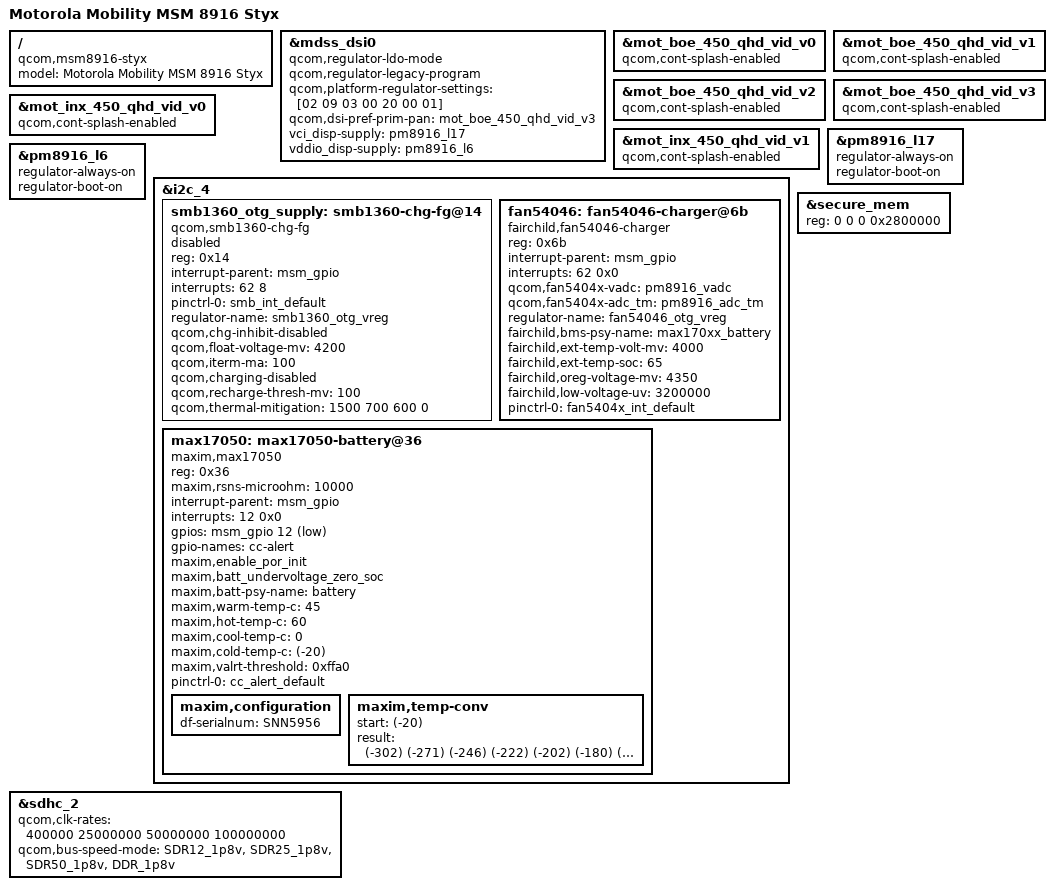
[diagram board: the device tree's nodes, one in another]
/* Copyright (c) 2014, Motorola Mobility LLC. All rights reserved.
*
* This program is free software; you can redistribute it and/or modify
* it under the terms of the GNU General Public License version 2 and
* only version 2 as published by the Free Software Foundation.
*
* This program is distributed in the hope that it will be useful,
* but WITHOUT ANY WARRANTY; without even the implied warranty of
* MERCHANTABILITY or FITNESS FOR A PARTICULAR PURPOSE.  See the
* GNU General Public License for more details.
*/

#include "msm8916-moto-common.dtsi"
#include "msm8916-camera-sensor-styx.dtsi"
#include "dsi-panel-mot-boe-450-qHD-video.dtsi"
#include "dsi-panel-mot-inx-450-qHD-video.dtsi"

/ {
	model = "Motorola Mobility MSM 8916 Styx";
	compatible = "qcom,msm8916-styx", "qcom,msm8916-moto", "qcom,msm8916";
};

&mdss_dsi0 {
	qcom,regulator-ldo-mode;
	qcom,regulator-legacy-program;
	qcom,platform-regulator-settings = [02 09 03 00 20 00 01];
	qcom,dsi-pref-prim-pan = <&mot_boe_450_qhd_vid_v3>;
	vci_disp-supply = <&pm8916_l17>;
	vddio_disp-supply = <&pm8916_l6>;
};

&mot_boe_450_qhd_vid_v0 {
	qcom,cont-splash-enabled;
};

&mot_boe_450_qhd_vid_v1 {
	qcom,cont-splash-enabled;
};

&mot_boe_450_qhd_vid_v2 {
	qcom,cont-splash-enabled;
};

&mot_boe_450_qhd_vid_v3 {
	qcom,cont-splash-enabled;
};

&mot_inx_450_qhd_vid_v0 {
	qcom,cont-splash-enabled;
};

&mot_inx_450_qhd_vid_v1 {
	qcom,cont-splash-enabled;
};

&pm8916_l17 {
	regulator-always-on;
	regulator-boot-on;
};

&pm8916_l6 {
	regulator-always-on;
	regulator-boot-on;
};

&i2c_4 {
	smb1360_otg_supply: smb1360-chg-fg@14 {
		status = "disabled";
		compatible = "qcom,smb1360-chg-fg";
		reg = <0x14>;
		interrupt-parent = <&msm_gpio>;
		interrupts = <62 8>;
		pinctrl-names = "default";
		pinctrl-0 = <&smb_int_default>;
		regulator-name = "smb1360_otg_vreg";

		qcom,chg-inhibit-disabled;
		qcom,float-voltage-mv = <4200>;
		qcom,iterm-ma = <100>;
		qcom,charging-disabled;
		qcom,recharge-thresh-mv = <100>;
		qcom,thermal-mitigation = <1500 700 600 0>;
	};

	fan54046: fan54046-charger@6b {
		compatible = "fairchild,fan54046-charger";
		reg = <0x6b>;

		interrupt-parent = <&msm_gpio>;
		interrupts = <62 0x0>;
		qcom,fan5404x-vadc = <&pm8916_vadc>;
		qcom,fan5404x-adc_tm = <&pm8916_adc_tm>;
		regulator-name = "fan54046_otg_vreg";

		fairchild,bms-psy-name = "max170xx_battery";
		fairchild,ext-temp-volt-mv = <4000>;
		fairchild,ext-temp-soc = <65>;
		fairchild,oreg-voltage-mv = <4350>;
		fairchild,low-voltage-uv = <3200000>;

		pinctrl-names = "default";
		pinctrl-0 = <&fan5404x_int_default>;
	};

	max17050: max17050-battery@36 {
		compatible = "maxim,max17050";
		reg = <0x36>;
		maxim,rsns-microohm = <10000>;

		interrupt-parent = <&msm_gpio>;
		interrupts = <12 0x0>;
		gpios = <&msm_gpio 12 0x11>; /* GPIOF_DIR_IN|GPIOF_EXPORT */
		gpio-names = "cc-alert";

		maxim,enable_por_init;
		maxim,batt_undervoltage_zero_soc;
		maxim,batt-psy-name = "battery";
		maxim,warm-temp-c = <45>;
		maxim,hot-temp-c = <60>;
		maxim,cool-temp-c = <0>;
		maxim,cold-temp-c = <(-20)>;

		maxim,valrt-threshold = <0xffa0>; /* Vmin 3.2V */

		pinctrl-names = "default";
		pinctrl-0 = <&cc_alert_default>;

		maxim,configuration {
			df-serialnum	= "SNN5956";

			/include/ "batterydata-ft40-lg.dtsi"
			/include/ "batterydata-ft40-sony.dtsi"
			/include/ "batterydata-ft40-lishen.dtsi"
		};

		maxim,temp-conv {
			start	= /bits/ 16 <(-20)>;	/* in degrees C */
			result	= /bits/ 16 <
				/* 1/10th C "real" temps corresponding start, start + 1, etc. fuel gauge temps in C */
				(-302) (-271) (-246) (-222) (-202) (-180) (-162) (-147) (-129) (-114)	/* -20 C ... -11 C */
				(-101) (-86)  (-72)  (-59)  (-48)  (-35)  (-23)  (-12)  (-2)   10	/* -10 C ... -1  C */
				22     32     42     51     62     72     82     91     99     110	/*  0  C ...  9  C */
				120    129    138    146    156    165    175    184    192    200	/*  10 C ...  19 C */
				210    220    230    238    247    256    266    275    285    294	/*  20 C ...  29 C */
				303    313    324    333    343    353    364    375    385    395	/*  30 C ...  39 C */
				407    419    430    441    453    466    479    492    505    520	/*  40 C ...  49 C */
				534    548    565    581    597    616    635    654    676    697	/*  50 C ...  59 C */
				721    747    775    800						/*  60 C ...  63 C */
			>;
		};
	};
};

&secure_mem {
	reg = <0 0 0 0x2800000>;
};

&sdhc_2 {
	qcom,clk-rates = <400000 25000000 50000000 100000000>;
	qcom,bus-speed-mode = "SDR12_1p8v", "SDR25_1p8v", "SDR50_1p8v", "DDR_1p8v";
};
